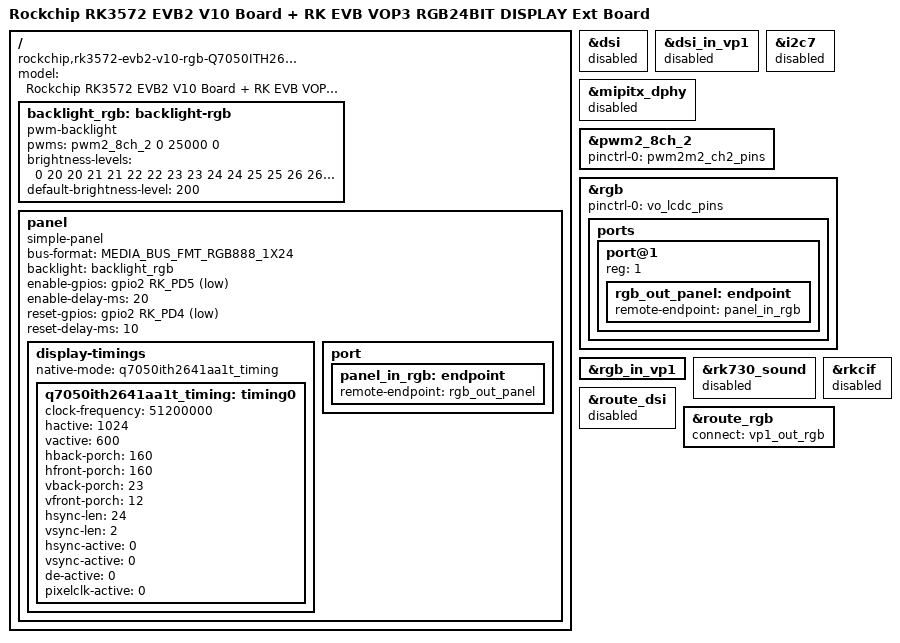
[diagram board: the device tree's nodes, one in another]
// SPDX-License-Identifier: (GPL-2.0+ OR MIT)
/*
 * Copyright (c) 2026 Rockchip Electronics Co., Ltd.
 */

/dts-v1/;

#include <dt-bindings/display/media-bus-format.h>
#include "rk3572-evb2-v10.dtsi"
#include "rk3572-android.dtsi"

/ {
	model = "Rockchip RK3572 EVB2 V10 Board + RK EVB VOP3 RGB24BIT DISPLAY Ext Board";
	compatible = "rockchip,rk3572-evb2-v10-rgb-Q7050ITH2641AA1T", "rockchip,rk3572";

	backlight_rgb: backlight-rgb {
		compatible = "pwm-backlight";
		pwms = <&pwm2_8ch_2 0 25000 0>;
		brightness-levels = <
			  0  20  20  21  21  22  22  23
			 23  24  24  25  25  26  26  27
			 27  28  28  29  29  30  30  31
			 31  32  32  33  33  34  34  35
			 35  36  36  37  37  38  38  39
			 40  41  42  43  44  45  46  47
			 48  49  50  51  52  53  54  55
			 56  57  58  59  60  61  62  63
			 64  65  66  67  68  69  70  71
			 72  73  74  75  76  77  78  79
			 80  81  82  83  84  85  86  87
			 88  89  90  91  92  93  94  95
			 96  97  98  99 100 101 102 103
			104 105 106 107 108 109 110 111
			112 113 114 115 116 117 118 119
			120 121 122 123 124 125 126 127
			128 129 130 131 132 133 134 135
			136 137 138 139 140 141 142 143
			144 145 146 147 148 149 150 151
			152 153 154 155 156 157 158 159
			160 161 162 163 164 165 166 167
			168 169 170 171 172 173 174 175
			176 177 178 179 180 181 182 183
			184 185 186 187 188 189 190 191
			192 193 194 195 196 197 198 199
			200 201 202 203 204 205 206 207
			208 209 210 211 212 213 214 215
			216 217 218 219 220 221 222 223
			224 225 226 227 228 229 230 231
			232 233 234 235 236 237 238 239
			240 241 242 243 244 245 246 247
			248 249 250 251 252 253 254 255
		>;
		default-brightness-level = <200>;
	};

	panel: panel {
		compatible = "simple-panel";
		bus-format = <MEDIA_BUS_FMT_RGB888_1X24>;
		backlight = <&backlight_rgb>;
		enable-gpios = <&gpio2 RK_PD5 GPIO_ACTIVE_LOW>;
		enable-delay-ms = <20>;
		reset-gpios = <&gpio2 RK_PD4 GPIO_ACTIVE_LOW>;
		reset-delay-ms = <10>;
		status = "okay";

		display-timings {
			native-mode = <&q7050ith2641aa1t_timing>;

			q7050ith2641aa1t_timing: timing0 {
				clock-frequency = <51200000>;
				hactive = <1024>;
				vactive = <600>;
				hback-porch = <160>;
				hfront-porch = <160>;
				vback-porch = <23>;
				vfront-porch = <12>;
				hsync-len = <24>;
				vsync-len = <2>;
				hsync-active = <0>;
				vsync-active = <0>;
				de-active = <0>;
				pixelclk-active = <0>;
			};
		};

		port {
			panel_in_rgb: endpoint {
				remote-endpoint = <&rgb_out_panel>;
			};
		};
	};
};

&dsi {
	status = "disabled";
};

&dsi_in_vp1 {
	status = "disabled";
};

/*
 * The devices on i2c7 have pins multiplexed with panel
 */
&i2c7 {
	status = "disabled";
};

&mipitx_dphy {
	status = "disabled";
};

&pwm2_8ch_2 {
	pinctrl-names = "active";
	pinctrl-0 = <&pwm2m2_ch2_pins>;
	status = "okay";
};

&rgb {
	status = "okay";
	pinctrl-names = "default";
	pinctrl-0 = <&vo_lcdc_pins>;

	ports {
		port@1 {
			reg = <1>;

			rgb_out_panel: endpoint {
				remote-endpoint = <&panel_in_rgb>;
			};
		};
	};
};

&rgb_in_vp1 {
	status = "okay";
};

/*
 * The pins of rk730_sound and backlight_rgb are multiplexed
 */
&rk730_sound {
	status = "disabled";
};

/*
 * The pins of rkcif and lcdc are multiplexed
 */
&rkcif {
	status = "disabled";
};

&route_dsi {
	status = "disabled";
};

&route_rgb {
	status = "okay";
	connect = <&vp1_out_rgb>;
};
